AUTOSAR XML (schema 4-0-3)
package /PATAC/MSM/ComponentTypes
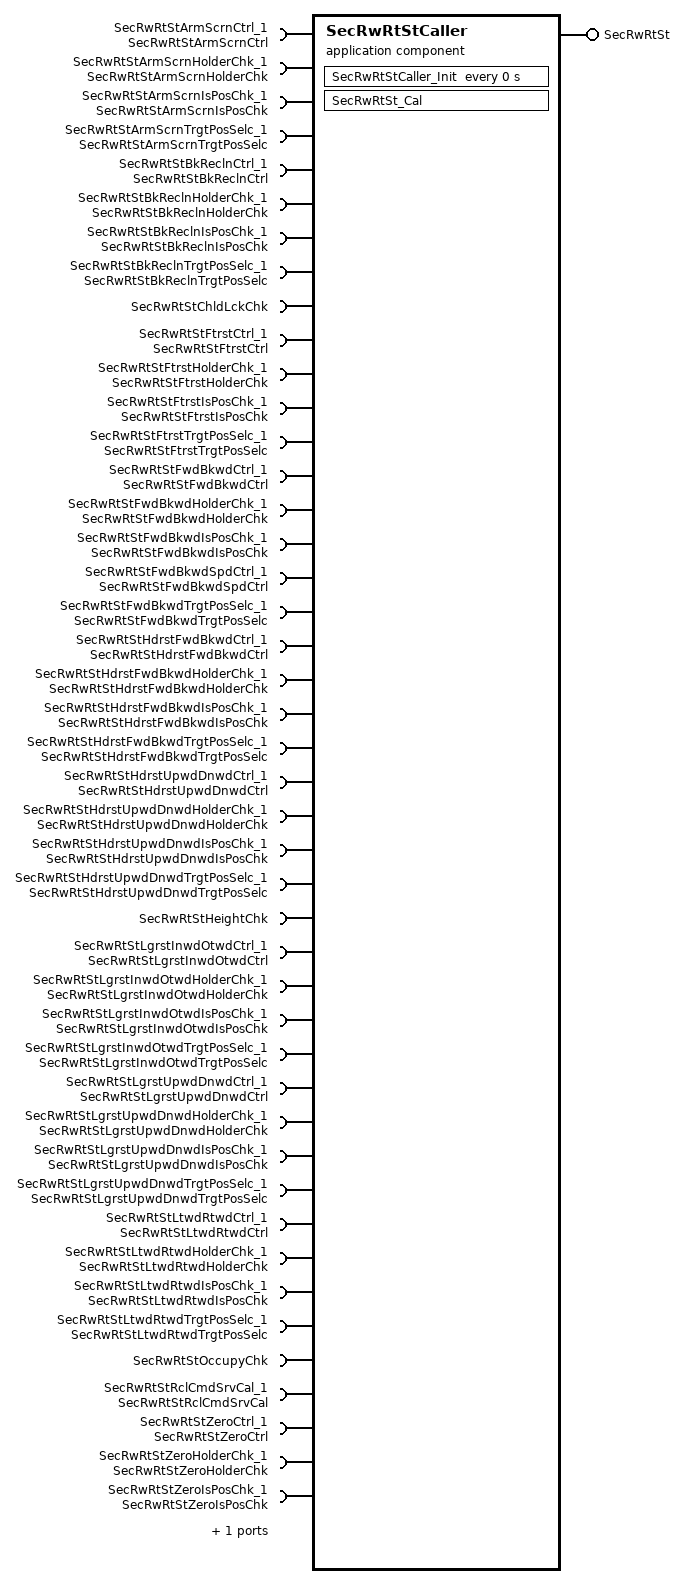
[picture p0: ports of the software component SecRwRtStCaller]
  application sw component type SecRwRtStCaller
    provide port SecRwRtSt: server-com-spec{operation=SecRwRtSt/Cal, queue-length=1}, provided-interface=SecRwRtSt
    45 x require port:
      SecRwRtStArmScrnCtrl_1: client-com-spec=SecRwRtStArmScrnCtrl/Cal, required-interface=SecRwRtStArmScrnCtrl
      SecRwRtStArmScrnHolderChk_1: client-com-spec=SecRwRtStArmScrnHolderChk/Cal, required-interface=SecRwRtStArmScrnHolderChk
      SecRwRtStArmScrnIsPosChk_1: client-com-spec=SecRwRtStArmScrnIsPosChk/Cal, required-interface=SecRwRtStArmScrnIsPosChk
      SecRwRtStArmScrnTrgtPosSelc_1: client-com-spec=SecRwRtStArmScrnTrgtPosSelc/Cal, required-interface=SecRwRtStArmScrnTrgtPosSelc
      SecRwRtStBkReclnCtrl_1: client-com-spec=SecRwRtStBkReclnCtrl/Cal, required-interface=SecRwRtStBkReclnCtrl
      SecRwRtStBkReclnHolderChk_1: client-com-spec=SecRwRtStBkReclnHolderChk/Cal, required-interface=SecRwRtStBkReclnHolderChk
      SecRwRtStBkReclnIsPosChk_1: client-com-spec=SecRwRtStBkReclnIsPosChk/Cal, required-interface=SecRwRtStBkReclnIsPosChk
      SecRwRtStBkReclnTrgtPosSelc_1: client-com-spec=SecRwRtStBkReclnTrgtPosSelc/Cal, required-interface=SecRwRtStBkReclnTrgtPosSelc
      SecRwRtStChldLckChk: client-com-spec=SecRwRtStChldLckChk/Cal, required-interface=SecRwRtStChldLckChk
      SecRwRtStFtrstCtrl_1: client-com-spec=SecRwRtStFtrstCtrl/Cal, required-interface=SecRwRtStFtrstCtrl
      SecRwRtStFtrstHolderChk_1: client-com-spec=SecRwRtStFtrstHolderChk/Cal, required-interface=SecRwRtStFtrstHolderChk
      SecRwRtStFtrstIsPosChk_1: client-com-spec=SecRwRtStFtrstIsPosChk/Cal, required-interface=SecRwRtStFtrstIsPosChk
      SecRwRtStFtrstTrgtPosSelc_1: client-com-spec=SecRwRtStFtrstTrgtPosSelc/Cal, required-interface=SecRwRtStFtrstTrgtPosSelc
      SecRwRtStFwdBkwdCtrl_1: client-com-spec=SecRwRtStFwdBkwdCtrl/Cal, required-interface=SecRwRtStFwdBkwdCtrl
      SecRwRtStFwdBkwdHolderChk_1: client-com-spec=SecRwRtStFwdBkwdHolderChk/Cal, required-interface=SecRwRtStFwdBkwdHolderChk
      SecRwRtStFwdBkwdIsPosChk_1: client-com-spec=SecRwRtStFwdBkwdIsPosChk/Cal, required-interface=SecRwRtStFwdBkwdIsPosChk
      SecRwRtStFwdBkwdSpdCtrl_1: client-com-spec=SecRwRtStFwdBkwdSpdCtrl/Cal, required-interface=SecRwRtStFwdBkwdSpdCtrl
      SecRwRtStFwdBkwdTrgtPosSelc_1: client-com-spec=SecRwRtStFwdBkwdTrgtPosSelc/Cal, required-interface=SecRwRtStFwdBkwdTrgtPosSelc
      SecRwRtStHdrstFwdBkwdCtrl_1: client-com-spec=SecRwRtStHdrstFwdBkwdCtrl/Cal, required-interface=SecRwRtStHdrstFwdBkwdCtrl
      SecRwRtStHdrstFwdBkwdHolderChk_1: client-com-spec=SecRwRtStHdrstFwdBkwdHolderChk/Cal, required-interface=SecRwRtStHdrstFwdBkwdHolderChk
      SecRwRtStHdrstFwdBkwdIsPosChk_1: client-com-spec=SecRwRtStHdrstFwdBkwdIsPosChk/Cal, required-interface=SecRwRtStHdrstFwdBkwdIsPosChk
      SecRwRtStHdrstFwdBkwdTrgtPosSelc_1: client-com-spec=SecRwRtStHdrstFwdBkwdTrgtPosSelc/Cal, required-interface=SecRwRtStHdrstFwdBkwdTrgtPosSelc
      SecRwRtStHdrstUpwdDnwdCtrl_1: client-com-spec=SecRwRtStHdrstUpwdDnwdCtrl/Cal, required-interface=SecRwRtStHdrstUpwdDnwdCtrl
      SecRwRtStHdrstUpwdDnwdHolderChk_1: client-com-spec=SecRwRtStHdrstUpwdDnwdHolderChk/Cal, required-interface=SecRwRtStHdrstUpwdDnwdHolderChk
      SecRwRtStHdrstUpwdDnwdIsPosChk_1: client-com-spec=SecRwRtStHdrstUpwdDnwdIsPosChk/Cal, required-interface=SecRwRtStHdrstUpwdDnwdIsPosChk
      SecRwRtStHdrstUpwdDnwdTrgtPosSelc_1: client-com-spec=SecRwRtStHdrstUpwdDnwdTrgtPosSelc/Cal, required-interface=SecRwRtStHdrstUpwdDnwdTrgtPosSelc
      SecRwRtStHeightChk: client-com-spec=SecRwRtStHeightChk/Cal, required-interface=SecRwRtStHeightChk
      SecRwRtStLgrstInwdOtwdCtrl_1: client-com-spec=SecRwRtStLgrstInwdOtwdCtrl/Cal, required-interface=SecRwRtStLgrstInwdOtwdCtrl
      SecRwRtStLgrstInwdOtwdHolderChk_1: client-com-spec=SecRwRtStLgrstInwdOtwdHolderChk/Cal, required-interface=SecRwRtStLgrstInwdOtwdHolderChk
      SecRwRtStLgrstInwdOtwdIsPosChk_1: client-com-spec=SecRwRtStLgrstInwdOtwdIsPosChk/Cal, required-interface=SecRwRtStLgrstInwdOtwdIsPosChk
      SecRwRtStLgrstInwdOtwdTrgtPosSelc_1: client-com-spec=SecRwRtStLgrstInwdOtwdTrgtPosSelc/Cal, required-interface=SecRwRtStLgrstInwdOtwdTrgtPosSelc
      SecRwRtStLgrstUpwdDnwdCtrl_1: client-com-spec=SecRwRtStLgrstUpwdDnwdCtrl/Cal, required-interface=SecRwRtStLgrstUpwdDnwdCtrl
      SecRwRtStLgrstUpwdDnwdHolderChk_1: client-com-spec=SecRwRtStLgrstUpwdDnwdHolderChk/Cal, required-interface=SecRwRtStLgrstUpwdDnwdHolderChk
      SecRwRtStLgrstUpwdDnwdIsPosChk_1: client-com-spec=SecRwRtStLgrstUpwdDnwdIsPosChk/Cal, required-interface=SecRwRtStLgrstUpwdDnwdIsPosChk
      SecRwRtStLgrstUpwdDnwdTrgtPosSelc_1: client-com-spec=SecRwRtStLgrstUpwdDnwdTrgtPosSelc/Cal, required-interface=SecRwRtStLgrstUpwdDnwdTrgtPosSelc
      SecRwRtStLtwdRtwdCtrl_1: client-com-spec=SecRwRtStLtwdRtwdCtrl/Cal, required-interface=SecRwRtStLtwdRtwdCtrl
      SecRwRtStLtwdRtwdHolderChk_1: client-com-spec=SecRwRtStLtwdRtwdHolderChk/Cal, required-interface=SecRwRtStLtwdRtwdHolderChk
      SecRwRtStLtwdRtwdIsPosChk_1: client-com-spec=SecRwRtStLtwdRtwdIsPosChk/Cal, required-interface=SecRwRtStLtwdRtwdIsPosChk
      SecRwRtStLtwdRtwdTrgtPosSelc_1: client-com-spec=SecRwRtStLtwdRtwdTrgtPosSelc/Cal, required-interface=SecRwRtStLtwdRtwdTrgtPosSelc
      SecRwRtStOccupyChk: client-com-spec=SecRwRtStOccupyChk/Cal, required-interface=SecRwRtStOccupyChk
      SecRwRtStRclCmdSrvCal_1: client-com-spec=SecRwRtStRclCmdSrvCal/Cal, required-interface=SecRwRtStRclCmdSrvCal
      SecRwRtStZeroCtrl_1: client-com-spec=SecRwRtStZeroCtrl/Cal, required-interface=SecRwRtStZeroCtrl
      SecRwRtStZeroHolderChk_1: client-com-spec=SecRwRtStZeroHolderChk/Cal, required-interface=SecRwRtStZeroHolderChk
      SecRwRtStZeroIsPosChk_1: client-com-spec=SecRwRtStZeroIsPosChk/Cal, required-interface=SecRwRtStZeroIsPosChk
      SecRwRtStZeroTrgtPosSelc_1: client-com-spec=SecRwRtStZeroTrgtPosSelc/Cal, required-interface=SecRwRtStZeroTrgtPosSelc
    behavior SecRwRtStCaller_InternalBehavior
      operation invoked event OIT_SecRwRtSt_Cal_SecRwRtSt_Cal: start-on-event=SecRwRtSt_Cal, operation=SecRwRtSt.Cal
      timing event SecRwRtStCaller_InitEvent: start-on-event=SecRwRtStCaller_Init, period=0
      runnable SecRwRtSt_Cal
        45 x sync call, all with timeout=0:
          SC_SecRwRtStArmScrnCtrl_1_Cal: operation=SecRwRtStArmScrnCtrl_1.Cal
          SC_SecRwRtStArmScrnHolderChk_1_Cal: operation=SecRwRtStArmScrnHolderChk_1.Cal
          SC_SecRwRtStArmScrnIsPosChk_1_Cal: operation=SecRwRtStArmScrnIsPosChk_1.Cal
          SC_SecRwRtStArmScrnTrgtPosSelc_1_Cal: operation=SecRwRtStArmScrnTrgtPosSelc_1.Cal
          SC_SecRwRtStBkReclnCtrl_1_Cal: operation=SecRwRtStBkReclnCtrl_1.Cal
          SC_SecRwRtStBkReclnHolderChk_1_Cal: operation=SecRwRtStBkReclnHolderChk_1.Cal
          SC_SecRwRtStBkReclnIsPosChk_1_Cal: operation=SecRwRtStBkReclnIsPosChk_1.Cal
          SC_SecRwRtStBkReclnTrgtPosSelc_1_Cal: operation=SecRwRtStBkReclnTrgtPosSelc_1.Cal
          SC_SecRwRtStChldLckChk_Cal: operation=SecRwRtStChldLckChk.Cal
          SC_SecRwRtStFtrstCtrl_1_Cal: operation=SecRwRtStFtrstCtrl_1.Cal
          SC_SecRwRtStFtrstHolderChk_1_Cal: operation=SecRwRtStFtrstHolderChk_1.Cal
          SC_SecRwRtStFtrstIsPosChk_1_Cal: operation=SecRwRtStFtrstIsPosChk_1.Cal
          SC_SecRwRtStFtrstTrgtPosSelc_1_Cal: operation=SecRwRtStFtrstTrgtPosSelc_1.Cal
          SC_SecRwRtStFwdBkwdCtrl_1_Cal: operation=SecRwRtStFwdBkwdCtrl_1.Cal
          SC_SecRwRtStFwdBkwdHolderChk_1_Cal: operation=SecRwRtStFwdBkwdHolderChk_1.Cal
          SC_SecRwRtStFwdBkwdIsPosChk_1_Cal: operation=SecRwRtStFwdBkwdIsPosChk_1.Cal
          SC_SecRwRtStFwdBkwdSpdCtrl_1_Cal: operation=SecRwRtStFwdBkwdSpdCtrl_1.Cal
          SC_SecRwRtStFwdBkwdTrgtPosSelc_1_Cal: operation=SecRwRtStFwdBkwdTrgtPosSelc_1.Cal
          SC_SecRwRtStHdrstFwdBkwdCtrl_1_Cal: operation=SecRwRtStHdrstFwdBkwdCtrl_1.Cal
          SC_SecRwRtStHdrstFwdBkwdHolderChk_1_Cal: operation=SecRwRtStHdrstFwdBkwdHolderChk_1.Cal
          SC_SecRwRtStHdrstFwdBkwdIsPosChk_1_Cal: operation=SecRwRtStHdrstFwdBkwdIsPosChk_1.Cal
          SC_SecRwRtStHdrstFwdBkwdTrgtPosSelc_1_Cal: operation=SecRwRtStHdrstFwdBkwdTrgtPosSelc_1.Cal
          SC_SecRwRtStHdrstUpwdDnwdCtrl_1_Cal: operation=SecRwRtStHdrstUpwdDnwdCtrl_1.Cal
          SC_SecRwRtStHdrstUpwdDnwdHolderChk_1_Cal: operation=SecRwRtStHdrstUpwdDnwdHolderChk_1.Cal
          SC_SecRwRtStHdrstUpwdDnwdIsPosChk_1_Cal: operation=SecRwRtStHdrstUpwdDnwdIsPosChk_1.Cal
          SC_SecRwRtStHdrstUpwdDnwdTrgtPosSelc_1_Cal: operation=SecRwRtStHdrstUpwdDnwdTrgtPosSelc_1.Cal
          SC_SecRwRtStHeightChk_Cal: operation=SecRwRtStHeightChk.Cal
          SC_SecRwRtStLgrstInwdOtwdCtrl_1_Cal: operation=SecRwRtStLgrstInwdOtwdCtrl_1.Cal
          SC_SecRwRtStLgrstInwdOtwdHolderChk_1_Cal: operation=SecRwRtStLgrstInwdOtwdHolderChk_1.Cal
          SC_SecRwRtStLgrstInwdOtwdIsPosChk_1_Cal: operation=SecRwRtStLgrstInwdOtwdIsPosChk_1.Cal
          SC_SecRwRtStLgrstInwdOtwdTrgtPosSelc_1_Cal: operation=SecRwRtStLgrstInwdOtwdTrgtPosSelc_1.Cal
          SC_SecRwRtStLgrstUpwdDnwdCtrl_1_Cal: operation=SecRwRtStLgrstUpwdDnwdCtrl_1.Cal
          SC_SecRwRtStLgrstUpwdDnwdHolderChk_1_Cal: operation=SecRwRtStLgrstUpwdDnwdHolderChk_1.Cal
          SC_SecRwRtStLgrstUpwdDnwdIsPosChk_1_Cal: operation=SecRwRtStLgrstUpwdDnwdIsPosChk_1.Cal
          SC_SecRwRtStLgrstUpwdDnwdTrgtPosSelc_1_Cal: operation=SecRwRtStLgrstUpwdDnwdTrgtPosSelc_1.Cal
          SC_SecRwRtStLtwdRtwdCtrl_1_Cal: operation=SecRwRtStLtwdRtwdCtrl_1.Cal
          SC_SecRwRtStLtwdRtwdHolderChk_1_Cal: operation=SecRwRtStLtwdRtwdHolderChk_1.Cal
          SC_SecRwRtStLtwdRtwdIsPosChk_1_Cal: operation=SecRwRtStLtwdRtwdIsPosChk_1.Cal
          SC_SecRwRtStLtwdRtwdTrgtPosSelc_1_Cal: operation=SecRwRtStLtwdRtwdTrgtPosSelc_1.Cal
          SC_SecRwRtStOccupyChk_Cal: operation=SecRwRtStOccupyChk.Cal
          SC_SecRwRtStRclCmdSrvCal_1_Cal: operation=SecRwRtStRclCmdSrvCal_1.Cal
          SC_SecRwRtStZeroCtrl_1_Cal: operation=SecRwRtStZeroCtrl_1.Cal
          SC_SecRwRtStZeroHolderChk_1_Cal: operation=SecRwRtStZeroHolderChk_1.Cal
          SC_SecRwRtStZeroIsPosChk_1_Cal: operation=SecRwRtStZeroIsPosChk_1.Cal
          SC_SecRwRtStZeroTrgtPosSelc_1_Cal: operation=SecRwRtStZeroTrgtPosSelc_1.Cal
      runnable SecRwRtStCaller_Init
  swc implementation SecRwRtStCaller_Implementation: behavior=SecRwRtStCaller_InternalBehavior
    code-descriptors:
      code Default: artifact-descriptors=autosar-engineering-object={short-label=Default, category=SWSRC}
package /PATAC/MSM/ModeAdjust/PortInterface
  46 x client server interface:
    SecRwRtSt
      operation Cal
    SecRwRtStArmScrnCtrl
      operation Cal
    SecRwRtStArmScrnHolderChk
      operation Cal
    SecRwRtStArmScrnIsPosChk
      operation Cal
    SecRwRtStArmScrnTrgtPosSelc
      operation Cal
    SecRwRtStBkReclnCtrl
      operation Cal
    SecRwRtStBkReclnHolderChk
      operation Cal
    SecRwRtStBkReclnIsPosChk
      operation Cal
    SecRwRtStBkReclnTrgtPosSelc
      operation Cal
    SecRwRtStChldLckChk
      operation Cal
    SecRwRtStFtrstCtrl
      operation Cal
    SecRwRtStFtrstHolderChk
      operation Cal
    SecRwRtStFtrstIsPosChk
      operation Cal
    SecRwRtStFtrstTrgtPosSelc
      operation Cal
    SecRwRtStFwdBkwdCtrl
      operation Cal
    SecRwRtStFwdBkwdHolderChk
      operation Cal
    SecRwRtStFwdBkwdIsPosChk
      operation Cal
    SecRwRtStFwdBkwdSpdCtrl
      operation Cal
    SecRwRtStFwdBkwdTrgtPosSelc
      operation Cal
    SecRwRtStHdrstFwdBkwdCtrl
      operation Cal
    SecRwRtStHdrstFwdBkwdHolderChk
      operation Cal
    SecRwRtStHdrstFwdBkwdIsPosChk
      operation Cal
    SecRwRtStHdrstFwdBkwdTrgtPosSelc
      operation Cal
    SecRwRtStHdrstUpwdDnwdCtrl
      operation Cal
    SecRwRtStHdrstUpwdDnwdHolderChk
      operation Cal
    SecRwRtStHdrstUpwdDnwdIsPosChk
      operation Cal
    SecRwRtStHdrstUpwdDnwdTrgtPosSelc
      operation Cal
    SecRwRtStHeightChk
      operation Cal
    SecRwRtStLgrstInwdOtwdCtrl
      operation Cal
    SecRwRtStLgrstInwdOtwdHolderChk
      operation Cal
    SecRwRtStLgrstInwdOtwdIsPosChk
      operation Cal
    SecRwRtStLgrstInwdOtwdTrgtPosSelc
      operation Cal
    SecRwRtStLgrstUpwdDnwdCtrl
      operation Cal
    SecRwRtStLgrstUpwdDnwdHolderChk
      operation Cal
    SecRwRtStLgrstUpwdDnwdIsPosChk
      operation Cal
    SecRwRtStLgrstUpwdDnwdTrgtPosSelc
      operation Cal
    SecRwRtStLtwdRtwdCtrl
      operation Cal
    SecRwRtStLtwdRtwdHolderChk
      operation Cal
    SecRwRtStLtwdRtwdIsPosChk
      operation Cal
    SecRwRtStLtwdRtwdTrgtPosSelc
      operation Cal
    SecRwRtStOccupyChk
      operation Cal
    SecRwRtStRclCmdSrvCal
      operation Cal
    SecRwRtStZeroCtrl
      operation Cal
    SecRwRtStZeroHolderChk
      operation Cal
    SecRwRtStZeroIsPosChk
      operation Cal
    SecRwRtStZeroTrgtPosSelc
      operation Cal
